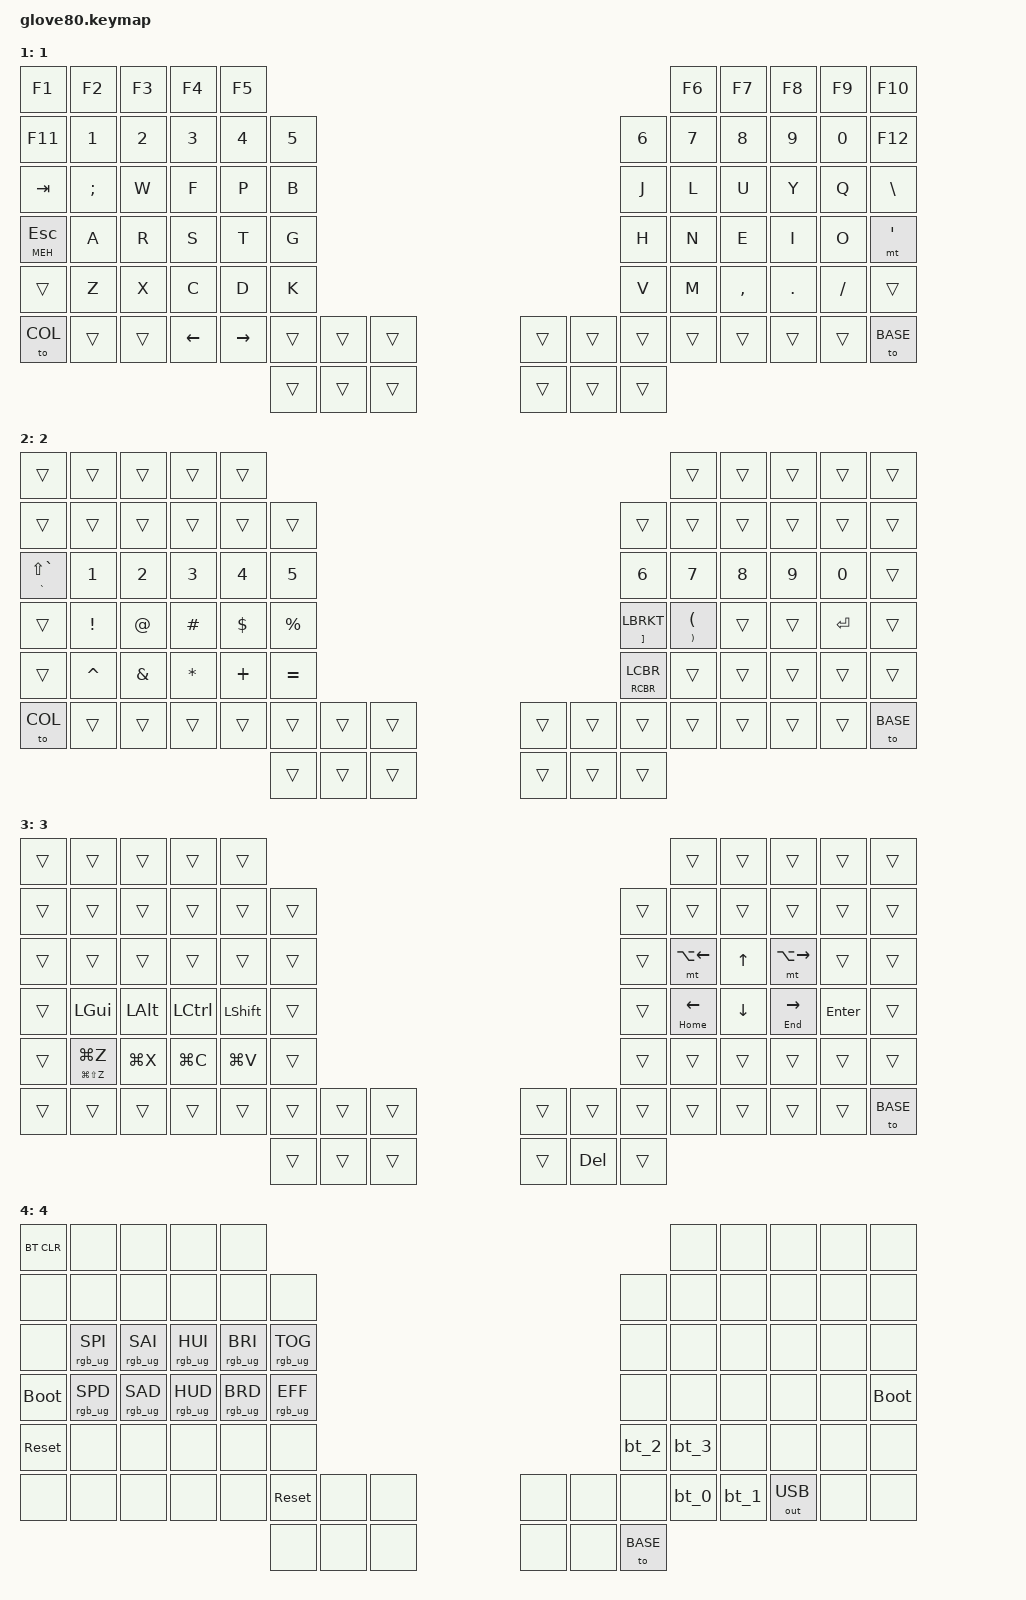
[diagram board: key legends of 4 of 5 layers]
/*
 * Copyright (c) 2020 The ZMK Contributors
 *
 * SPDX-License-Identifier: MIT
 */

#include <behaviors.dtsi>
#include <dt-bindings/zmk/keys.h>
#include <dt-bindings/zmk/bt.h>
#include <dt-bindings/zmk/ext_power.h>
#include <dt-bindings/zmk/outputs.h>
#include <dt-bindings/zmk/rgb.h>

// layers
#define BASE QWE
#define QWE 0
#define COL 1
#define SYM 2
#define NAV 3
#define MGC 4

// Custom keys
#define MEH             LS(LC(LALT))
#define HYP             LS(LC(LG(LALT)))
#define ESC_MEH         &mt LS(LC(LALT)) ESC
#define SPC_NAV         &mt NAV SPACE
#define ENT_SYM         &mt SYM ENTER
#define TLD_GRV         &mt GRAVE LS(GRAVE)

#define XXX &none
#define ___ &trans


#define NAV_LEFT        &mt HOME LEFT
#define NAV_RIGHT       &mt END RIGHT
#define NAV_UP          &kp UP
#define NAV_DOWN        &kp DOWN
#define WRD_LEFT        &mt LA(LEFT)
#define WRD_RIGHT       &mt LA(RIGHT)


#undef UNDO
#undef CUT
#undef COPY
#undef PASTE
#define UNDO            &mt LG(LS(Z))  LG(Z)
#define CUT             &kp LG(X)
#define COPY            &kp LG(C)
#define PASTE           &kp LG(V)


/ {
    behaviors {
        // For the "layer" key, it'd nice to be able to use it as either a shift or a toggle.
        // Configure it as a tap dance, so the first tap (or hold) is a &mo and the second tap is a &to
        lt_td: tap_dance_0 {
            compatible = "zmk,behavior-tap-dance";
            #binding-cells = <0>;
            tapping-term-ms = <200>;
            bindings = <&mo>, <&to>;
        };
        meh_hyp; meh_hyp {
            compatible = "zmk,behavior-tap-dance";
            #binding-cells = <0>;
            tapping-term-ms = <200>;
            bindings = <&kp MEH>, <&kp HYP>;
        };
    };

    macros {
        bt_0: bt_profile_macro_0 {
            compatible = "zmk,behavior-macro";
            #binding-cells = <0>;
            bindings
                = <&out OUT_BLE>,
                  <&bt BT_SEL 0>;
        };

        bt_1: bt_profile_macro_1 {
            compatible = "zmk,behavior-macro";
            #binding-cells = <0>;
            bindings
                = <&out OUT_BLE>,
                  <&bt BT_SEL 1>;
        };

        bt_2: bt_profile_macro_2 {
            compatible = "zmk,behavior-macro";
            #binding-cells = <0>;
            bindings
                = <&out OUT_BLE>,
                  <&bt BT_SEL 2>;
        };

        bt_3: bt_profile_macro_3 {
            compatible = "zmk,behavior-macro";
            #binding-cells = <0>;
            bindings
                = <&out OUT_BLE>,
                  <&bt BT_SEL 3>;
        };
    };

    keymap {
        compatible = "zmk,keymap";

        0 { // QWERTY
            // ---------------------------------------------------------------------------------------------------------------------------------
            // |  F1   |  F2 |  F3 |  F4  |  F5  |                                                               |  F6   |  F7   |  F8  |   F9  |  F10 |
            // |  =    |  1  |  2  |  3   |  4   |  5   |                                                 |  6   |   7   |   8   |  9   |   0   |   -  |
            // |  TAB  |  Q  |  W  |  E   |  R   |  T   |                                                 |  Y   |   U   |   I   |  O   |   P   |   \  |
            // |  ESC  |  A  |  S  |  D   |  F   |  G   |                                                 |  H   |   J   |   K   |  L   |   ;   |   '  |
            // |   `   |  Z  |  X  |  C   |  V   |  B   | LSHFT | LCTRL | LOWER | | LGUI  | RCTRL | RSHFT |  N   |   M   |   ,   |  .   |   /   | PGUP |
            // | MAGIC | HOME| END | LEFT | RIGHT|      | BSPC  | DEL   | LALT  | | RALT  | RET   | SPACE |      |  UP   | DOWN  |  [   |   ]   | PGDN |

            bindings = <
            &kp F1         &kp F2   &kp F3      &kp F4      &kp F5                                                                                                             &kp F6  &kp F7      &kp F8      &kp F9      &kp F10
            &kp EQUAL      &kp N1   &kp N2      &kp N3      &kp N4      &kp N5                                                                                         &kp N6  &kp N7  &kp N8      &kp N9      &kp N0      &kp F12
            &kp TAB        &kp Q    &kp W       &kp E       &kp R       &kp T                                                                                          &kp Y   &kp U   &kp I       &kp O       &kp P       &kp BSLH
            ESC_MEH        &kp A    &kp S       &kp D       &kp F       &kp G                                                                                          &kp H   &kp J   &kp K       &kp L       &kp SEMI    &kp SQT
            &kp LSHIFT     &kp Z    &kp X       &kp C       &kp V       &kp B   &kp LGUI    &kp LCTRL   &lt_td NAV NAV          XXX         XXX            &MEH_HYP    &kp N   &kp M   &kp COMMA   &kp DOT     &kp FSLH    &kp MINUS
            &mo MGC        &kp HOME &kp END     &kp LEFT    &kp RIGHT           SPC_NAV     &kp LSHIFT  &kp LALT                XXX         &kp BACKSPACE  ENT_SYM             &kp UP  &kp DOWN    &kp LBKT    &kp RBKT    &kp PLUS
            >;
        };

        1 { // ColemakQI
            bindings = <
            &kp F1          &kp F2          &kp F3          &kp F4          &kp F5                                                                                                                                                                          &kp F6          &kp F7          &kp F8          &kp F9          &kp F10             
            &kp F11         &kp N1          &kp N2          &kp N3          &kp N4          &kp N5                                                                                                                                          &kp N6          &kp N7          &kp N8          &kp N9          &kp N0          &kp F12
            &kp TAB         &kp SEMI        &kp W           &kp F           &kp P           &kp B                                                                                                                                           &kp J           &kp L           &kp U           &kp Y           &kp Q           &kp BSLH      
            &mt MEH ESC     &kp A           &kp R           &kp S           &kp T           &kp G                                                                                                                                           &kp H           &kp N           &kp E           &kp I           &kp O           &mt SQT
            ___             &kp Z           &kp X           &kp C           &kp D           &kp K                                                                                                                                           &kp V           &kp M           &kp COMMA       &kp DOT         &kp FSLH        ___
            &to COL         ___             ___             &kp LEFT        &kp RIGHT                       ___             ___             ___                                             ___             ___             ___                             ___             ___             ___             ___             &to BASE
                                                                                                            ___             ___             ___                                             ___             ___             ___             
            >;
        };

        2 { // SYMBOLS
            bindings = <
            ___             ___             ___             ___             ___                                                                                                                                                                             ___             ___             ___             ___             ___             
            ___             ___             ___             ___             ___             ___                                                                                                                                             ___             ___             ___             ___             ___             ___
            TLD_GRV         &kp N1          &kp N2          &kp N3          &kp N4          &kp N5                                                                                                                                          &kp N6          &kp N7          &kp N8          &kp N9          &kp N0          ___
            ___             &kp EXCL        &kp AT          &kp HASH        &kp DLLR        &kp PRCNT                                                                                                                                       &mt RBKT LBRKT  &mt RPAR LPAR   ___             ___             &kp ENTER       ___
            ___             &kp CARET       &kp AMPS        &kp ASTRK       &kp PLUS        &kp EQL                                                                                                                                         &mt RCBR LCBR   ___             ___             ___             ___             ___        
            &to COL         ___             ___             ___             ___                             ___             ___             ___                                             ___             ___             ___                             ___             ___             ___             ___             &to BASE
                                                                                                            ___             ___             ___                                             ___             ___             ___             
            >;
        }

        3 { // Navigation
            bindings = <
            ___             ___             ___             ___             ___                                                                                                                                                                             ___             ___             ___             ___             ___             
            ___             ___             ___             ___             ___             ___                                                                                                                                             ___             ___             ___             ___             ___             ___
            ___             ___             ___             ___             ___             ___                                                                                                                                             ___             WRD_LEFT        NAV_UP          WRD_RIGHT       ___             ___
            ___             &kp LGUI        &kp LALT        &kp LCTRL       &kp LSHIFT      ___                                                                                                                                             ___             NAV_LEFT        NAV_DOWN        NAV_RIGHT       &kp Enter       ___
            ___             UNDO            CUT             COPY            PASTE           ___                                                                                                                                             ___             ___             ___             ___             ___             ___
            ___             ___             ___             ___             ___                             ___             ___             ___                                             ___             ___             ___                             ___             ___             ___             ___             &to BASE
                                                                                                            ___             ___             ___                                             ___             &kp DEL         ___             
            >;
        }

        4 { // MAGIC (native Glove80 layer)
            bindings = <
            &bt BT_CLR        &none               &none           &none           &none                                                                                                           &none      &none      &none      &none      &none
            &none             &none               &none           &none           &none           &none                                                                                &none      &none      &none      &none      &none      &none
            &none             &rgb_ug RGB_SPI     &rgb_ug RGB_SAI &rgb_ug RGB_HUI &rgb_ug RGB_BRI &rgb_ug RGB_TOG                                                                      &none      &none      &none      &none      &none      &none
            &bootloader       &rgb_ug RGB_SPD     &rgb_ug RGB_SAD &rgb_ug RGB_HUD &rgb_ug RGB_BRD &rgb_ug RGB_EFF                                                                      &none      &none      &none      &none      &none      &bootloader
            &sys_reset        &none               &none           &none           &none           &none           &bt_2     &bt_3     &none            &none     &none     &none       &none      &none      &none      &none      &none      &sys_reset
            &none             &none               &none           &none           &none                           &bt_0     &bt_1     &out OUT_USB     &none     &none     &none                  &none      &none      &none      &none      &to BASE
            >;
        };
    };
};
